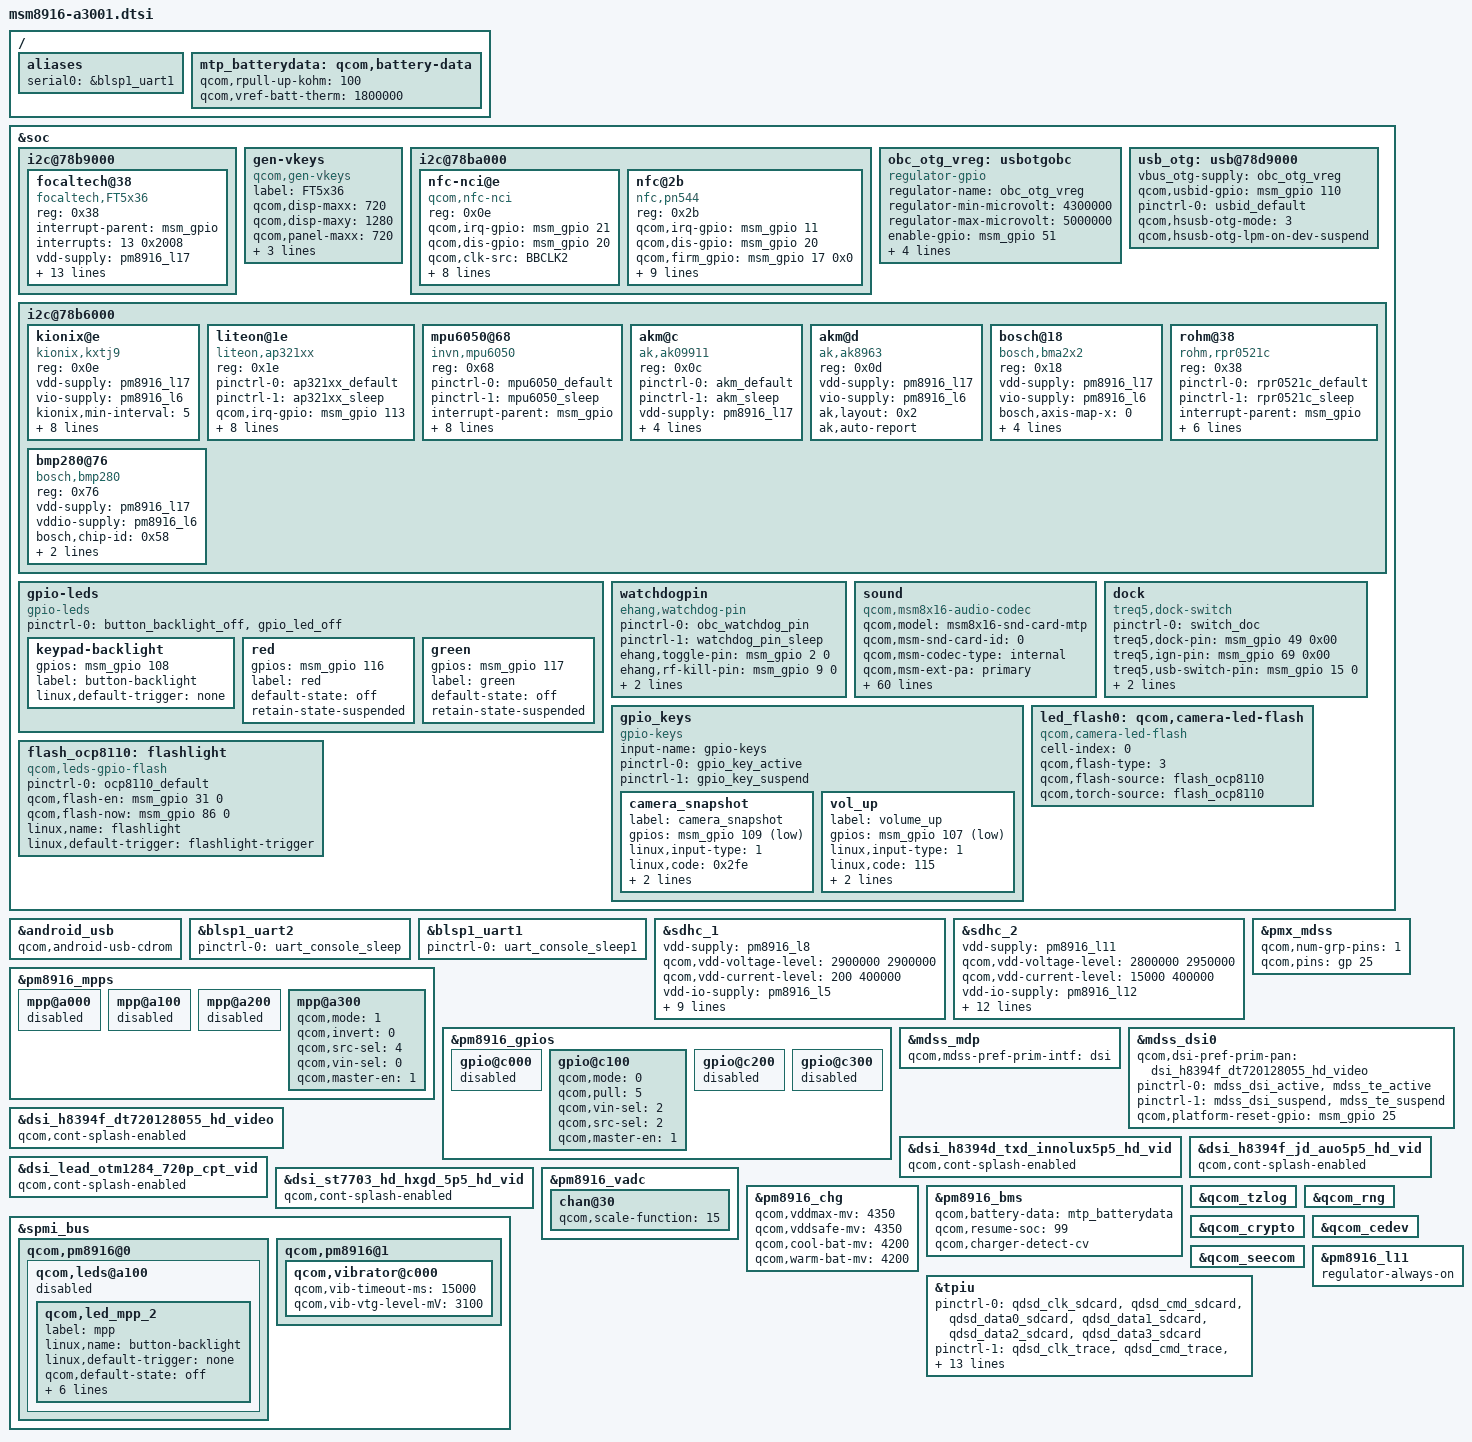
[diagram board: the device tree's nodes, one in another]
/* Copyright (c) 2014, The Linux Foundation. All rights reserved.
 *
 * This program is free software; you can redistribute it and/or modify
 * it under the terms of the GNU General Public License version 2 and
 * only version 2 as published by the Free Software Foundation.
 *
 * This program is distributed in the hope that it will be useful,
 * but WITHOUT ANY WARRANTY; without even the implied warranty of
 * MERCHANTABILITY or FITNESS FOR A PARTICULAR PURPOSE.  See the
 * GNU General Public License for more details.
 */

#include "msm8916.dtsi"
#include "msm8916-pinctrl-a3001.dtsi"
/*#include "msm8916-camera-sensor-mtp.dtsi"*/
#include "ehang_camera_a3001.dtsi"

/ {
	aliases {
		/* by skj */
		serial0 = &blsp1_uart1;
	};
};

&soc {
		i2c@78b9000 { /* BLSP1 QUP5 */
		focaltech@38 {
			compatible = "focaltech,FT5x36";
			reg = <0x38>;
			interrupt-parent = <&msm_gpio>;
			interrupts = <13 0x2008>;
			vdd-supply = <&pm8916_l17>;
			vcc_i2c-supply = <&pm8916_l6>;
			pinctrl-names = "pmx_ts_active","pmx_ts_suspend";
			pinctrl-0 = <&ts_int_active &ts_reset_active>;
            /*Modified by jiao.shp for tp gesture in 20141113 START*/
            #if 0
			pinctrl-1 = <&ts_int_suspend &ts_reset_suspend>;
            #else
            pinctrl-1 = <&ts_int_active &ts_reset_suspend>;
            #endif
            /*Modified by jiao.shp for tp gesture in 20141113 END*/
			focaltech,family-id = <8>;
			focaltech,max_touch_point = <5>;
			focaltech,reset-gpio = <&msm_gpio 12 0x00>;
			focaltech,irq-gpio = <&msm_gpio 13 0x00>;
			focaltech,display-coords = <0 0 720 1280>;
			focaltech,panel-coords = <0 0 720 1420>;
			focaltech,button-map= <139 172 158>;
			focaltech,no-force-update;
			focaltech,i2c-pull-up;
			focaltech,auto_clb;
		};
	};
	gen-vkeys {
		compatible = "qcom,gen-vkeys";
		label = "FT5x36";
		qcom,disp-maxx = <720>;
		qcom,disp-maxy = <1280>;
		qcom,panel-maxx = <720>;
		qcom,panel-maxy = <1408>;
		qcom,key-codes = <139 172 158>;
		qcom,y-offset = <0>;
	};

	i2c@78ba000 { /* BLSP1 QUP6 */
		nfc-nci@e {
			compatible = "qcom,nfc-nci";
			reg = <0x0e>;
			qcom,irq-gpio = <&msm_gpio 21 0x00>;
			qcom,dis-gpio = <&msm_gpio 20 0x00>;
			qcom,clk-src = "BBCLK2";
			qcom,clk-en-gpio = <&msm_gpio 0 0x00>;
			interrupt-parent = <&msm_gpio>;
			interrupts = <21 0>;
			interrupt-names = "nfc_irq";
			pinctrl-names = "nfc_active","nfc_suspend";
			pinctrl-0 = <&nfc_int_active &nfc_disable_active>;
			pinctrl-1 = <&nfc_int_suspend &nfc_disable_suspend>;
			qcom,clk-gpio = <&pm8916_gpios 2 0>;
			clocks = <&clock_rpm clk_bb_clk2_pin>;
			clock-names = "ref_clk";
		};
	};

	/* by skj*/
	i2c@78ba000 { /* BLSP1 QUP6 */
		nfc@2b {
			compatible = "nfc,pn544";
			reg = <0x2b>;
			qcom,irq-gpio = <&msm_gpio 11 0x00>;
			qcom,dis-gpio = <&msm_gpio 20 0x00>;
			qcom,firm_gpio = <&msm_gpio 17 0x0>;
			qcom,clk-src = "BBCLK2";
			qcom,clk-en-gpio = <&msm_gpio 21 0x00>;
			interrupt-parent = <&msm_gpio>;
			interrupts = <11 0>;
			interrupt-names = "nfc_irq";
			pinctrl-names = "nfc_active","nfc_suspend";
			pinctrl-0 = <&nfc_int_active &nfc_disable_active>;
			pinctrl-1 = <&nfc_int_suspend &nfc_disable_suspend>;
			qcom,clk-gpio = <&pm8916_gpios 2 0>;
			clocks = <&clock_rpm clk_bb_clk2_pin>;
			clock-names = "ref_clk";
			};
	};

	/* by skj*/
	obc_otg_vreg:usbotgobc { 
		compatible = "regulator-gpio";
		regulator-name = "obc_otg_vreg";
		regulator-min-microvolt = <4300000>;
		regulator-max-microvolt = <5000000>;
		
		enable-gpio = <&msm_gpio 51 0x00>;
		gpios = <&msm_gpio 111 0x00>;
		states = <4300000 0x0
				5000000 0x1>;
		enable-active-high;
		regulator-type = "voltage";
	};
	
	usb_otg: usb@78d9000 {
		vbus_otg-supply = <&obc_otg_vreg>;
		qcom,usbid-gpio = <&msm_gpio 110 0>;
		pinctrl-names = "default";
		pinctrl-0 = <&usbid_default>;
		qcom,hsusb-otg-mode = <3>;
		qcom,hsusb-otg-lpm-on-dev-suspend;
	};		
	
	i2c@78b6000 { /* BLSP1 QUP2 */
		kionix@e{
			compatible = "kionix,kxtj9";
			reg = <0x0e>;
			vdd-supply = <&pm8916_l17>;
			vio-supply = <&pm8916_l6>;
			kionix,min-interval = <5>;
			kionix,init-interval = <200>;
			kionix,axis-map-x = <0>;
			kionix,axis-map-y = <1>;
			kionix,axis-map-z = <2>;
			kionix,negate-x;
	        kionix,negate-y;		
			kionix,g-range = <2>;
			kionix,res-12bit;
		};
		liteon@1e {
			compatible = "liteon,ap321xx";
			reg = <0x1e>;
			pinctrl-names = "default","sleep";
			pinctrl-0 = <&ap321xx_default>;
			pinctrl-1 = <&ap321xx_sleep>;
			qcom,irq-gpio = <&msm_gpio 113 0>;
			interrupt-parent = <&msm_gpio>;
			interrupts = <113 0>;
			liteon,ps-thdh = <200>; 			
			liteon,ps-thdl = <160>;
			liteon,ps-high = <160>; 			
			liteon,ps-low = <120>;
			vdd-supply = <&pm8916_l17>;
			vio-supply = <&pm8916_l6>;
		};
	mpu6050@68 { 
			compatible = "invn,mpu6050";
			reg = <0x68>;
			pinctrl-names = "mpu_default","mpu_sleep";
			pinctrl-0 = <&mpu6050_default>;
			pinctrl-1 = <&mpu6050_sleep>;
			interrupt-parent = <&msm_gpio>;
			interrupts = <118 0x2>;
			vdd-supply = <&pm8916_l17>;
			vlogic-supply = <&pm8916_l16>;
			vi2c-supply = <&pm8916_l6>;
			invn,use-interrupt;
			invn,gpio-int = <&msm_gpio 118 0x2>;
			invn,place = "Portrait Down Back Side";
			invn,gpio-en = <&msm_gpio 98 0x2>;
		};
		
	akm@c {
		compatible = "ak,ak09911";
		reg = <0x0c>;
		pinctrl-names = "default","sleep";
		pinctrl-0 = <&akm_default>;
		pinctrl-1 = <&akm_sleep>;
		vdd-supply = <&pm8916_l17>;
		vio-supply = <&pm8916_l6>;
		akm,layout = <0x4>;
		akm,gpio_rstn = <&msm_gpio 36 0x0>;
		akm,auto-report;
	};
	
	akm@d {
		compatible = "ak,ak8963";
		reg = <0x0d>;
		/*pinctrl-names = "default","sleep";
		pinctrl-0 = <&akm_default>;
		pinctrl-1 = <&akm_sleep>;*/
		vdd-supply = <&pm8916_l17>;
		vio-supply = <&pm8916_l6>;
		ak,layout = <0x2>;
		/*ak,gpio_rstn = <&msm_gpio 36 0x0>; */
		ak,auto-report;
	};
	
	bosch@18 {
		compatible = "bosch,bma2x2";
		reg = <0x18>;
		vdd-supply = <&pm8916_l17>;
		vio-supply = <&pm8916_l6>;
		bosch,axis-map-x = <0>;
		bosch,axis-map-y = <1>;
		bosch,axis-map-z = <2>;
		bosch,negate-y;
		/*bosch,negate-z;*/
		bosch,g-range = <3>;
	};

	
	rohm@38 { /* Ambient light and proximity sensor */
		compatible = "rohm,rpr0521c";
		reg = <0x38>;
		pinctrl-names = "default","sleep";
		pinctrl-0 = <&rpr0521c_default>;
		pinctrl-1 = <&rpr0521c_sleep>;
		interrupt-parent = <&msm_gpio>;
		interrupts = <120 0x2002>;
		vdd-supply = <&pm8916_l17>;
		vio-supply = <&pm8916_l6>;
		rpr0521c,irq-gpio = <&msm_gpio 120 0x2002>;
		rpr0521c,prox_th_min = <50>;
		rpr0521c,prox_th_max = <150>;
	};
	
	bmp280@76 {
		reg = <0x76>;
		compatible = "bosch,bmp280";
		vdd-supply = <&pm8916_l17>;
		vddio-supply = <&pm8916_l6>;
		bosch,chip-id = <0x58>;
		bosch,oversample = <3>;
		bosch,period = <1000>;
	};
/* by shengweiguang end */
	};

	/* by skj beidou and leds*/
	gpio-leds {
		compatible = "gpio-leds";
		pinctrl-names = "default";
		/* by skj*/
		pinctrl-0 = <&button_backlight_off &gpio_led_off>;
	
		keypad-backlight {
			gpios = <&msm_gpio 108 0>;
			label = "button-backlight";
			linux,default-trigger = "none";
		};
	
		red {
			gpios = <&msm_gpio 116 0>;
			label = "red";
			default-state = "off";
			retain-state-suspended;
		};

		green {
			gpios = <&msm_gpio 117 0>;
			label = "green";
			default-state = "off";
			retain-state-suspended;
		};
	};
	watchdogpin {
		compatible = "ehang,watchdog-pin";
		pinctrl-names = "default", "watchdog_pin_sleep";
		pinctrl-0 = <&obc_watchdog_pin>;		
		pinctrl-1 = <&watchdog_pin_sleep>;
		ehang,toggle-pin = <&msm_gpio 2 0>;
		ehang,rf-kill-pin = <&msm_gpio 9 0>;
		ehang,high-delay=<1000>;
		ehang,low-delay=<1000>;
	};
	sound {
		compatible = "qcom,msm8x16-audio-codec";
		qcom,model = "msm8x16-snd-card-mtp";
		qcom,msm-snd-card-id = <0>;
		qcom,msm-codec-type = "internal";
		qcom,msm-ext-pa = "primary";
		qcom,msm-mclk-freq = <9600000>;
		qcom,msm-mbhc-hphl-swh = <1>;
		qcom,msm-mbhc-gnd-swh = <0>;
		qcom,msm-micbias1-ext-cap;
		qcom,msm-hs-micbias-type = "internal";
		qcom,audio-routing =
			"RX_BIAS", "MCLK",
			"SPK_RX_BIAS", "MCLK",
			"INT_LDO_H", "MCLK",
			"MIC BIAS External", "Handset Mic",
			"MIC BIAS Internal2", "Headset Mic",
			"MIC BIAS External", "Secondary Mic",
			"AMIC1", "MIC BIAS External",
			"AMIC2", "MIC BIAS Internal2",
			"AMIC3", "MIC BIAS External",
			"DMIC1", "MIC BIAS Internal1",
			"MIC BIAS Internal1", "Digital Mic1",
			"DMIC2", "MIC BIAS Internal1",
			"MIC BIAS Internal1", "Digital Mic2";
		pinctrl-names = "cdc_lines_act",
				"cdc_lines_sus",
				"cdc_lines_sec_ext_act",
				"cdc_lines_sec_ext_sus",
				"cross_conn_det_act",
				"cross_conn_det_sus";
		pinctrl-0 = <&cdc_pdm_lines_act>;
		pinctrl-1 = <&cdc_pdm_lines_sus>;
		pinctrl-2 = <&cdc_pdm_lines_act &cdc_ext_pa_act
						&cdc_ext_pa_ws_act>;
		pinctrl-3 = <&cdc_pdm_lines_sus &cdc_ext_pa_sus
						&cdc_ext_pa_ws_sus>;
		pinctrl-4 = <&cross_conn_det_act>;
		pinctrl-5 = <&cross_conn_det_sus>;
		qcom,cdc-us-euro-gpios = <&msm_gpio 120 0>;
		asoc-platform = <&pcm0>, <&pcm1>, <&voip>, <&voice>,
				<&loopback>, <&compress>, <&hostless>,
				<&afe>, <&lsm>, <&routing>, <&lpa>;
		asoc-platform-names = "msm-pcm-dsp.0", "msm-pcm-dsp.1",
				"msm-voip-dsp", "msm-pcm-voice", "msm-pcm-loopback",
				"msm-compress-dsp", "msm-pcm-hostless", "msm-pcm-afe",
				"msm-lsm-client", "msm-pcm-routing", "msm-pcm-lpa";
		asoc-cpu = <&dai_pri_auxpcm>, <&dai_hdmi>,
				<&dai_mi2s0>, <&dai_mi2s1>, <&dai_mi2s2>, <&dai_mi2s3>,
				<&sb_0_rx>, <&sb_0_tx>, <&sb_1_rx>, <&sb_1_tx>,
				<&sb_3_rx>, <&sb_3_tx>, <&sb_4_rx>, <&sb_4_tx>,
				<&bt_sco_rx>, <&bt_sco_tx>, <&int_fm_rx>, <&int_fm_tx>,
				<&afe_pcm_rx>, <&afe_pcm_tx>, <&afe_proxy_rx>, <&afe_proxy_tx>,
				<&incall_record_rx>, <&incall_record_tx>, <&incall_music_rx>,
				<&incall_music_2_rx>;
		asoc-cpu-names = "msm-dai-q6-auxpcm.1", "msm-dai-q6-hdmi.8",
				"msm-dai-q6-mi2s.0", "msm-dai-q6-mi2s.1",
				"msm-dai-q6-mi2s.2", "msm-dai-q6-mi2s.3",
				"msm-dai-q6-dev.16384", "msm-dai-q6-dev.16385",
				"msm-dai-q6-dev.16386", "msm-dai-q6-dev.16387",
				"msm-dai-q6-dev.16390", "msm-dai-q6-dev.16391",
				"msm-dai-q6-dev.16392", "msm-dai-q6-dev.16393",
				"msm-dai-q6-dev.12288", "msm-dai-q6-dev.12289",
				"msm-dai-q6-dev.12292", "msm-dai-q6-dev.12293",
				"msm-dai-q6-dev.224", "msm-dai-q6-dev.225",
				"msm-dai-q6-dev.241", "msm-dai-q6-dev.240",
				"msm-dai-q6-dev.32771", "msm-dai-q6-dev.32772",
				"msm-dai-q6-dev.32773", "msm-dai-q6-dev.32770";
		asoc-codec = <&stub_codec>, <&pm8916_tombak_dig>;
		asoc-codec-names = "msm-stub-codec.1", "tombak_codec";
		qcom,ext-spk-amp-gpio = <&msm_gpio 16 0>;
		qcom,hp-spk-switch-gpio = <&msm_gpio 3 0>;
	};
/*
	a8_power_lost_hm {
		compatible = "a8-hm-power-lost";
		pinctrl-names = "default";
		pinctrl-0 = <&power_lost_pin>;		
		qcom,irq-gpio = <&msm_gpio 89 0x01>;
		qcom,irq-ign-gpio = <&msm_gpio 69 0x01>;
		interrupt-names = "power_lost", "ign_active";
		interrupt-parent = <&msm_gpio>;
		interrupts = <&msm_gpio 89 1>, <&msm_gpio 69 1>;
		a8,wan-off-delay = <0>;
		a8,wlan-off-delay = <0>;
		a8,plat-off-delay = <19000>;
		status = "okay";
	};
*/
	dock {
		compatible = "treq5,dock-switch";
		pinctrl-names = "default";
		pinctrl-0 = <&switch_doc>;
		treq5,dock-pin = <&msm_gpio 49 0x00>;
		treq5,ign-pin = <&msm_gpio 69 0x00>;
		treq5,usb-switch-pin = <&msm_gpio 15 0>;
		interrupt-names = "docking", "ignition";
		interrupt-parent = <&msm_gpio>;
		interrupts = <&msm_gpio 49 1>, <&msm_gpio 69 1>;
		status = "okay";
	};
};

/* add by shengweiguang for usb gadget 20150817 begin */
&android_usb {
	qcom,android-usb-cdrom;
};
/* add by shengweiguang for usb gadget 20150817 end */


&blsp1_uart2 {
	status = "ok";
	pinctrl-names = "default";
	pinctrl-0 = <&uart_console_sleep>;
};

&soc {
	gpio_keys {
		compatible = "gpio-keys";
		input-name = "gpio-keys";
		pinctrl-names = "tlmm_gpio_key_active","tlmm_gpio_key_suspend";
		pinctrl-0 = <&gpio_key_active>;
		pinctrl-1 = <&gpio_key_suspend>;

		camera_snapshot {
			label = "camera_snapshot";
			gpios = <&msm_gpio 109 0x1>;
			linux,input-type = <1>;
			linux,code = <0x2fe>;
			gpio-key,wakeup;
			debounce-interval = <15>;
		};

		vol_up {
			label = "volume_up";
			gpios = <&msm_gpio 107 0x1>;
			linux,input-type = <1>;
			linux,code = <115>;
			gpio-key,wakeup;
			debounce-interval = <15>;
		};
	};
};

&blsp1_uart1 {
	/* by skj*/
	pinctrl-names = "default";
	pinctrl-0 = <&uart_console_sleep1>;	
	status = "ok";
};

&sdhc_1 {
	vdd-supply = <&pm8916_l8>;
	qcom,vdd-voltage-level = <2900000 2900000>;
	qcom,vdd-current-level = <200 400000>;

	vdd-io-supply = <&pm8916_l5>;
	qcom,vdd-io-always-on;
	qcom,vdd-io-lpm-sup;
	qcom,vdd-io-voltage-level = <1800000 1800000>;
	qcom,vdd-io-current-level = <200 60000>;

	pinctrl-names = "active", "sleep";
	pinctrl-0 = <&sdc1_clk_on &sdc1_cmd_on &sdc1_data_on>;
	pinctrl-1 = <&sdc1_clk_off &sdc1_cmd_off &sdc1_data_off>;

	qcom,nonremovable;

	status = "ok";
};

&sdhc_2 {
	vdd-supply = <&pm8916_l11>;
	qcom,vdd-voltage-level = <2800000 2950000>;
	qcom,vdd-current-level = <15000 400000>;

	vdd-io-supply = <&pm8916_l12>;
	qcom,vdd-io-voltage-level = <1800000 2950000>;
	qcom,vdd-io-current-level = <200 50000>;

	pinctrl-names = "active", "sleep";
	pinctrl-0 = <&sdc2_clk_on &sdc2_cmd_on &sdc2_data_on &sdc2_cd_on>;
	pinctrl-1 = <&sdc2_clk_off &sdc2_cmd_off &sdc2_data_off &sdc2_cd_off>;

	#address-cells = <0>;
	interrupt-parent = <&sdhc_2>;
	interrupts = <0 1 2>;
	#interrupt-cells = <1>;
	interrupt-map-mask = <0xffffffff>;
	interrupt-map = <0 &intc 0 125 0
			1 &intc 0 221 0
			2 &msm_gpio 38 0>;
	interrupt-names = "hc_irq", "pwr_irq", "status_irq";
	cd-gpios = <&msm_gpio 38 0x0>;

	status = "ok";
};

&pm8916_mpps {
	mpp@a000 { /* MPP 1 */
		/* VDD_PX */
		status = "disabled";
	};

	mpp@a100 { /* MPP 2 */
		/* HR LED */
		status = "disabled";
	};

	mpp@a200 { /* MPP 3 */
		/* VREF DAC */
		status = "disabled";
	};

	mpp@a300 { /* MPP 4 */
		/* Backlight PWM */
		qcom,mode = <1>;		/* Digital output */
		qcom,invert = <0>;		/* Disable invert */
		qcom,src-sel = <4>;		/* DTEST1 */
		qcom,vin-sel = <0>;		/* VPH_PWR */
		qcom,master-en = <1>;		/* Enable MPP */
	};
};

&pm8916_gpios {
	gpio@c000 { /* GPIO 1 */
		/* Battery UICC Alarm */
		status = "disabled";
	};

	gpio@c100 { /* GPIO 2 */
		/* NFC_CLK_REQ */
		qcom,mode = <0>; /* QPNP_PIN_MODE_DIG_IN */
		qcom,pull = <5>; /* QPNP_PIN_PULL_NO */
		qcom,vin-sel = <2>; /* QPNP_PIN_VIN2 */
		qcom,src-sel = <2>; /* QPNP_PIN_SEL_FUNC_1 */
		qcom,master-en = <1>;
	};

	gpio@c200 { /* GPIO 3 */
		/* External regulator control for WTR */
		status = "disabled";
	};

	gpio@c300 { /* GPIO 4 */
		/* External regulator control for APC */
		status = "disabled";
	};
};

#include "dsi-panel-lead-otm1284-cpt-720p-video.dtsi"
#include "dsi-panel-h8394d-txd-innolux5p5-hd-video.dtsi"
#include "dsi-panel-h8394f-jd-auo5p5-hd-video.dtsi"
#include "dsi-panel-st7703-hxgd5p5-hd-video.dtsi"
#include "dsi-panel-h8394f-dt720128055.dtsi"

&mdss_mdp {
	qcom,mdss-pref-prim-intf = "dsi";
};

&pmx_mdss {
	qcom,num-grp-pins = <1>;
	qcom,pins = <&gp 25>;
};

&mdss_dsi0 {
	qcom,dsi-pref-prim-pan = <&dsi_h8394f_dt720128055_hd_video>;
/*	qcom,dsi-pref-prim-pan = <&dsi_h8394d_txd_innolux5p5_hd_vid>;*/
	pinctrl-names = "mdss_default", "mdss_sleep";
	pinctrl-0 = <&mdss_dsi_active &mdss_te_active>;
	pinctrl-1 = <&mdss_dsi_suspend &mdss_te_suspend>;

	qcom,platform-reset-gpio = <&msm_gpio 25 0>;
};

&dsi_h8394f_dt720128055_hd_video {
      qcom,cont-splash-enabled;
};

&dsi_h8394d_txd_innolux5p5_hd_vid {
      qcom,cont-splash-enabled;
};

&dsi_h8394f_jd_auo5p5_hd_vid {
      qcom,cont-splash-enabled;
};

&dsi_lead_otm1284_720p_cpt_vid {
       qcom,cont-splash-enabled;
};

&dsi_st7703_hd_hxgd_5p5_hd_vid {
       qcom,cont-splash-enabled;
};

&pm8916_vadc {
	chan@30 {
	/* by skj*/
		qcom,scale-function = <15>;
	};
};

&pm8916_chg {
	status = "ok";
	/* by skj */
	qcom,vddmax-mv = <4350>;
	qcom,vddsafe-mv = <4350>;
	qcom,cool-bat-mv = <4200>;
	qcom,warm-bat-mv = <4200>;	
};

/ {
	mtp_batterydata: qcom,battery-data {
		qcom,rpull-up-kohm = <100>;
		qcom,vref-batt-therm = <1800000>;

		#include "batterydata-a3001-1850mah.dtsi"
	};
};

&pm8916_bms {
	status = "ok";
	qcom,battery-data = <&mtp_batterydata>;
	/* by skj*/
	qcom,resume-soc = <99>;
	qcom,charger-detect-cv;		
};

&spmi_bus {
	qcom,pm8916@0 {
		qcom,leds@a100 {
			status = "disabled"; /* by skj */
			qcom,led_mpp_2 {
				label = "mpp";
				linux,name = "button-backlight";
				linux,default-trigger = "none";
				qcom,default-state = "off";
				qcom,max-current = <40>;
				qcom,current-setting = <5>;
				qcom,id = <6>;
				qcom,mode = "manual";
				qcom,source-sel = <1>;
				qcom,mode-ctrl = <0x60>;
			};
		};
	};
};

&qcom_tzlog {
	status = "okay";
};

&qcom_rng {
	status = "okay";
};

&qcom_crypto {
	status = "okay";
};

&qcom_cedev {
	status = "okay";
};

&qcom_seecom {
	status = "okay";
};

/* CoreSight */
&tpiu {
      pinctrl-names = "sdcard", "trace", "swduart",
		      "swdtrc", "jtag", "spmi";
       /* NIDnT */
      pinctrl-0 = <&qdsd_clk_sdcard &qdsd_cmd_sdcard
                  &qdsd_data0_sdcard &qdsd_data1_sdcard
                  &qdsd_data2_sdcard &qdsd_data3_sdcard>;
      pinctrl-1 = <&qdsd_clk_trace &qdsd_cmd_trace
                  &qdsd_data0_trace &qdsd_data1_trace
                  &qdsd_data2_trace &qdsd_data3_trace>;
      pinctrl-2 = <&qdsd_cmd_swduart &qdsd_data0_swduart
                  &qdsd_data1_swduart &qdsd_data2_swduart
                  &qdsd_data3_swduart>;
      pinctrl-3 = <&qdsd_clk_swdtrc &qdsd_cmd_swdtrc
                  &qdsd_data0_swdtrc &qdsd_data1_swdtrc
                  &qdsd_data2_swdtrc &qdsd_data3_swdtrc>;
      pinctrl-4 = <&qdsd_cmd_jtag &qdsd_data0_jtag
                  &qdsd_data1_jtag &qdsd_data2_jtag
                  &qdsd_data3_jtag>;
      pinctrl-5 = <&qdsd_clk_spmi &qdsd_cmd_spmi
                  &qdsd_data0_spmi &qdsd_data3_spmi>;
};

&spmi_bus {
	qcom,pm8916@1 {
		qcom,vibrator@c000 {
			status = "okay";
			qcom,vib-timeout-ms = <15000>;
			qcom,vib-vtg-level-mV = <3100>;
		};
	};
};

&soc {
	led_flash0: qcom,camera-led-flash {
		cell-index = <0>;
		compatible = "qcom,camera-led-flash";
		qcom,flash-type = <3>;
		qcom,flash-source = <&flash_ocp8110>;
		qcom,torch-source = <&flash_ocp8110>;
	};
	flash_ocp8110:flashlight {
		compatible = "qcom,leds-gpio-flash";
		status = "okay";
		pinctrl-names = "ocp8110_default";
		pinctrl-0 = <&ocp8110_default>;
		qcom,flash-en = <&msm_gpio 31 0>;
		qcom,flash-now = <&msm_gpio 86 0>;
		linux,name = "flashlight";
		linux,default-trigger = "flashlight-trigger";
	};
};

/* by skj*/
&pm8916_l11 {
	regulator-always-on;
};
